# ATSAM4CMS32C_0 device description
Architecture: CORTEX-M4; Family: SAM4; Series: SAM4CM
Registers are 32-bit, read-write, no defined reset value unless marked. A register's access mark holds for its fields unless they carry their own. Offsets are from the block's base; [hi:lo] are bit positions; {n}, {i} and the like mark numbered series.

## CHIPID — Chip Identifier
Instances: CHIPID 0x400E0740
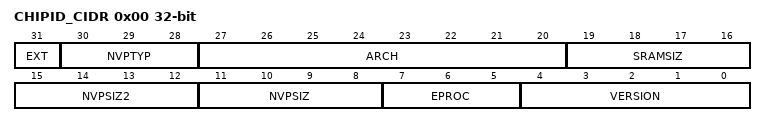
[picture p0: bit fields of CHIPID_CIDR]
0x00 CHIPID_CIDR ro — Chip ID Register
  [31] EXT — Extension Flag
  [30:28] NVPTYP — Nonvolatile Program Memory Type
    0=ROM; 1=ROMLESS (ROMless or on-chip Flash); 2=FLASH (Embedded Flash Memory); 3=ROM_FLASH (ROM and Embedded Flash Memory- NVPSIZ is ROM size- NVPSIZ2 is Flash size); 4=SRAM (SRAM emulating ROM)
  [27:20] ARCH — Architecture Identifier
    100=SAM4CxxC (SAM4CxC (100-pin version))
  [19:16] SRAMSIZ — Internal SRAM Size
    0=_48K (48 Kbytes); 1=_192K (192 Kbytes); 2=_384K (384 Kbytes); 3=_6K (6 Kbytes); 4=_24K (24 Kbytes); 5=_4K (4 Kbytes); 6=_80K (80 Kbytes); 7=_160K (160 Kbytes); 8=_8K (8 Kbytes); 9=_16K (16 Kbytes); 10=_32K (32 Kbytes); 11=_64K (64 Kbytes); 12=_128K (128 Kbytes); 13=_256K (256 Kbytes); 14=_96K (96 Kbytes); 15=_512K (512 Kbytes)
  [15:12] NVPSIZ2 — Second Nonvolatile Program Memory Size
    0=NONE; 1=_8K (8 Kbytes); 2=_16K (16 Kbytes); 3=_32K (32 Kbytes); 5=_64K (64 Kbytes); 7=_128K (128 Kbytes); 9=_256K (256 Kbytes); 10=_512K (512 Kbytes); 12=_1024K (1024 Kbytes); 14=_2048K (2048 Kbytes)
  [11:8] NVPSIZ — Nonvolatile Program Memory Size
    0=NONE; 1=_8K (8 Kbytes); 2=_16K (16 Kbytes); 3=_32K (32 Kbytes); 5=_64K (64 Kbytes); 7=_128K (128 Kbytes); 8=_160K (160 Kbytes); 9=_256K (256 Kbytes); 10=_512K (512 Kbytes); 12=_1024K (1024 Kbytes); 14=_2048K (2048 Kbytes)
  [7:5] EPROC — Embedded Processor
    1=ARM946ES; 2=ARM7TDMI; 3=CM3 (Cortex-M3); 4=ARM920T; 5=ARM926EJS; 6=CA5 (Cortex-A5); 7=CM4 (Cortex-M4)
  [4:0] VERSION — Version of the Device
0x04 CHIPID_EXID ro — Chip ID Extension Register
  [31:0] EXID — Chip ID Extension
    1=SAM4CMP (SAM4C + 3-phase EMAFE); 2=SAM4CMS (SAM4C + 2-phase EMAFE)

## CMCC — Cortex-M Cache Controller
Instances: CMCC0 0x4007C000, CMCC1 0x48018000
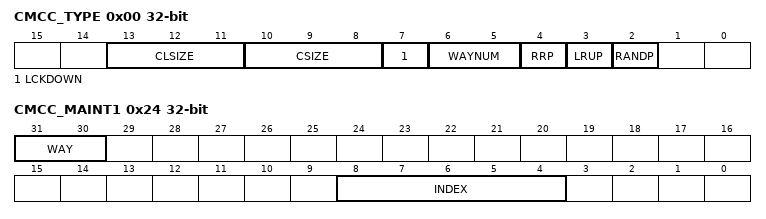
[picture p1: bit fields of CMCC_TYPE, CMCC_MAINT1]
0x00 CMCC_TYPE ro — Cache Controller Type Register
  [13:11] CLSIZE — Cache LIne Size
    0=CLSIZE_1KB (Cache Line Size 4 Bytes); 1=CLSIZE_2KB (Cache Line Size 8 Bytes); 2=CLSIZE_4KB (Cache Line Size 16 Bytes); 3=CLSIZE_8KB (Cache Line Size 32 Bytes)
  [10:8] CSIZE — Data Cache Size
    0=CSIZE_1KB (Data Cache Size 1 Kbyte); 1=CSIZE_2KB (Data Cache Size 2 Kbytes); 2=CSIZE_4KB (Data Cache Size 4 Kbytes); 3=CSIZE_8KB (Data Cache Size 8 Kbytes)
  [7] LCKDOWN — Lock Down Supported
  [6:5] WAYNUM — Number of Ways
    0=DMAPPED (Direct Mapped Cache); 1=ARCH2WAY (2-WAY set associative); 2=ARCH4WAY (4-WAY set associative); 3=ARCH8WAY (8-WAY set associative)
  [4] RRP — Random Selection Policy Supported
  [3] LRUP — Least Recently Used Policy Supported
  [2] RANDP — Random Selection Policy Supported
0x08 CMCC_CTRL wo — Cache Controller Control Register
  [0] CEN — Cache Controller Enable
0x0C CMCC_SR ro — Cache Controller Status Register
  [0] CSTS — Cache Controller Status
0x20 CMCC_MAINT0 wo — Cache Controller Maintenance Register 0
  [0] INVALL — Cache Controller Invalidate All
0x24 CMCC_MAINT1 wo — Cache Controller Maintenance Register 1
  [31:30] WAY — Invalidate Way
    {v}=Way {v} is selection for index invalidation (v=0..3)
  [8:4] INDEX — Invalidate Index
0x28 CMCC_MCFG — Cache Controller Monitor Configuration Register
  [1:0] MODE — Cache Controller Monitor Counter Mode
    0=CYCLE_COUNT (Cycle counter); 1=IHIT_COUNT (Instruction hit counter); 2=DHIT_COUNT (Data hit counter)
0x2C CMCC_MEN — Cache Controller Monitor Enable Register
  [0] MENABLE — Cache Controller Monitor Enable
0x30 CMCC_MCTRL wo — Cache Controller Monitor Control Register
  [0] SWRST — Monitor
0x34 CMCC_MSR ro — Cache Controller Monitor Status Register
  [31:0] EVENT_CNT — Monitor Event Counter

## EFC — Embedded Flash Controller
Instances: EFC0 0x400E0A00, EFC1 0x400E0C00
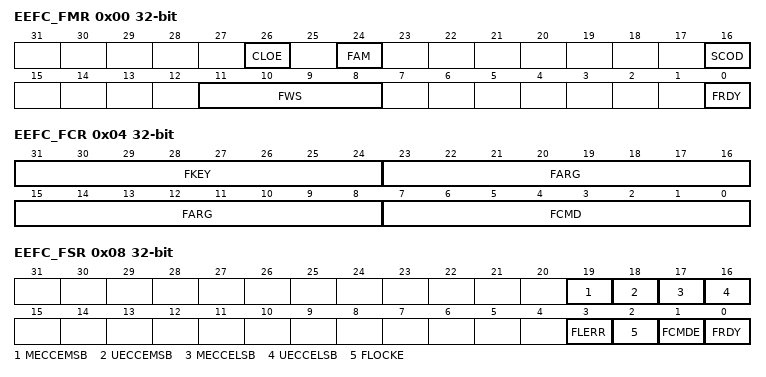
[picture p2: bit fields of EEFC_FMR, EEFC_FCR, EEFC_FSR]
0x00 EEFC_FMR — EEFC Flash Mode Register
  [26] CLOE — Code Loop Optimization Enable
  [24] FAM — Flash Access Mode
  [16] SCOD — Sequential Code Optimization Disable
  [11:8] FWS — Flash Wait State
  [0] FRDY — Flash Ready Interrupt Enable
0x04 EEFC_FCR wo — EEFC Flash Command Register
  [31:24] FKEY — Flash Writing Protection Key
    90=PASSWD (The 0x5A value enables the command defined by the bits of the register. If the field is written with a different value, the write is not performed and no action is started.)
  [23:8] FARG — Flash Command Argument
  [7:0] FCMD — Flash Command
    0=GETD (Get Flash descriptor); 1=WP (Write page); 2=WPL (Write page and lock); 3=EWP (Erase page and write page); 4=EWPL (Erase page and write page then lock); 5=EA (Erase all); 6=EPL (Erase plane); 7=EPA (Erase pages); 8=SLB (Set lock bit); 9=CLB (Clear lock bit); 10=GLB (Get lock bit); 11=SGPB (Set GPNVM bit); 12=CGPB (Clear GPNVM bit); 13=GGPB (Get GPNVM bit); 14=STUI (Start read unique identifier); 15=SPUI (Stop read unique identifier); 16=GCALB (Get CALIB bit); 17=ES (Erase sector); 18=WUS (Write user signature); 19=EUS (Erase user signature); 20=STUS (Start read user signature); 21=SPUS (Stop read user signature)
0x08 EEFC_FSR ro — EEFC Flash Status Register
  [19] MECCEMSB — Multiple ECC Error on MSB Part of the Memory Flash Data Bus
  [18] UECCEMSB — Unique ECC Error on MSB Part of the Memory Flash Data Bus
  [17] MECCELSB — Multiple ECC Error on LSB Part of the Memory Flash Data Bus
  [16] UECCELSB — Unique ECC Error on LSB Part of the Memory Flash Data Bus
  [3] FLERR — Flash Error Status
  [2] FLOCKE — Flash Lock Error Status
  [1] FCMDE — Flash Command Error Status
  [0] FRDY — Flash Ready Status
0x0C EEFC_FRR ro — EEFC Flash Result Register
  [31:0] FVALUE — Flash Result Value

## Notices in the file
SAM Software Package License
Copyright (c) %copyright_year%, Atmel Corporation
All rights reserved.
Redistribution and use in source and binary forms, with or without
modification, are permitted provided that the following condition is met:
- Redistributions of source code must retain the above copyright notice,
this list of conditions and the disclaimer below.
Atmel's name may not be used to endorse or promote products derived from
this software without specific prior written permission.
DISCLAIMER:  THIS SOFTWARE IS PROVIDED BY ATMEL "AS IS" AND ANY EXPRESS OR
IMPLIED WARRANTIES, INCLUDING, BUT NOT LIMITED TO, THE IMPLIED WARRANTIES OF
MERCHANTABILITY, FITNESS FOR A PARTICULAR PURPOSE AND NON-INFRINGEMENT ARE
DISCLAIMED. IN NO EVENT SHALL ATMEL BE LIABLE FOR ANY DIRECT, INDIRECT,
INCIDENTAL, SPECIAL, EXEMPLARY, OR CONSEQUENTIAL DAMAGES (INCLUDING, BUT NOT
LIMITED TO, PROCUREMENT OF SUBSTITUTE GOODS OR SERVICES; LOSS OF USE, DATA,
OR PROFITS; OR BUSINESS INTERRUPTION) HOWEVER CAUSED AND ON ANY THEORY OF
LIABILITY, WHETHER IN CONTRACT, STRICT LIABILITY, OR TORT (INCLUDING
NEGLIGENCE OR OTHERWISE) ARISING IN ANY WAY OUT OF THE USE OF THIS SOFTWARE,
EVEN IF ADVISED OF THE POSSIBILITY OF SUCH DAMAGE.
